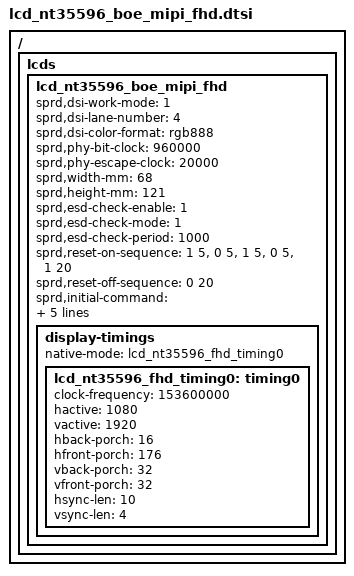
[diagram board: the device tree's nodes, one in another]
// SPDX-License-Identifier: GPL-2.0-only
/*
 * Unisoc NT35696 Truly LCD config DTS file
 *
 * Copyright (C) 2021, Unisoc Inc.
 */
/ {fragment {
	target-path = "/";
	__overlay__ {
		lcds {
			lcd_nt35596_boe_mipi_fhd: lcd_nt35596_boe_mipi_fhd {

				sprd,dsi-work-mode = <1>; /* video burst mode */
				sprd,dsi-lane-number = <4>;
				sprd,dsi-color-format = "rgb888";

				sprd,phy-bit-clock = <960000>; /* kbps */
				sprd,phy-escape-clock = <20000>; /* kHz */

				sprd,width-mm = <68>;
				sprd,height-mm = <121>;

				sprd,esd-check-enable = <1>;
				sprd,esd-check-mode = <1>;
				sprd,esd-check-period = <1000>;
				/* sprd,esd-check-regs = <0x0A>; */
				/* sprd,esd-return-code = <0x9C>; */

				sprd,reset-on-sequence = <1 5>, <0 5>, <1 5>, <0 5>, <1 20>;
				sprd,reset-off-sequence = <0 20>;

				sprd,initial-command = [
					23 00 00 02 FF EE
					23 0A 00 02 18 40 /* OSC ON 10ms */
					23 14 00 02 18 00 /* OSC OFF 20ms */

					23 00 00 02 FF 01
					23 00 00 02 FB 01
					23 00 00 02 00 01
					23 00 00 02 01 55
					23 00 00 02 02 40
					23 00 00 02 05 40
					23 00 00 02 06 94
					23 00 00 02 07 94
					23 00 00 02 08 0C
					23 00 00 02 11 19
					23 00 00 02 12 19
					23 00 00 02 13 03
					23 00 00 02 14 94
					23 00 00 02 15 15
					23 00 00 02 16 15
					23 00 00 02 6D 22
					23 00 00 02 0B AF
					23 00 00 02 0C AF
					23 00 00 02 0E AB
					23 00 00 02 0F A4
					23 00 00 02 58 82
					23 00 00 02 59 02
					23 00 00 02 5A 02
					23 00 00 02 5B 02
					23 00 00 02 5C 82
					23 00 00 02 5D 82
					23 00 00 02 5E 02
					23 00 00 02 5F 02
					23 00 00 02 75 00
					23 00 00 02 76 00
					23 00 00 02 77 00
					23 00 00 02 78 11
					23 00 00 02 79 00
					23 00 00 02 7A 30
					23 00 00 02 7B 00
					23 00 00 02 7C 4A
					23 00 00 02 7D 00
					23 00 00 02 7E 62
					23 00 00 02 7F 00
					23 00 00 02 80 78
					23 00 00 02 81 00
					23 00 00 02 82 8C
					23 00 00 02 83 00
					23 00 00 02 84 9E
					23 00 00 02 85 00
					23 00 00 02 86 AE
					23 00 00 02 87 00
					23 00 00 02 88 E4
					23 00 00 02 89 01
					23 00 00 02 8A 0E
					23 00 00 02 8B 01
					23 00 00 02 8C 4C
					23 00 00 02 8D 01
					23 00 00 02 8E 7B
					23 00 00 02 8F 01
					23 00 00 02 90 C2
					23 00 00 02 91 01
					23 00 00 02 92 FB
					23 00 00 02 93 01
					23 00 00 02 94 FC
					23 00 00 02 95 02
					23 00 00 02 96 34
					23 00 00 02 97 02
					23 00 00 02 98 79
					23 00 00 02 99 02
					23 00 00 02 9A A4
					23 00 00 02 9B 02
					23 00 00 02 9C DD
					23 00 00 02 9D 03
					23 00 00 02 9E 05
					23 00 00 02 9F 03
					23 00 00 02 A0 39
					23 00 00 02 A2 03
					23 00 00 02 A3 48
					23 00 00 02 A4 03
					23 00 00 02 A5 58
					23 00 00 02 A6 03
					23 00 00 02 A7 6A
					23 00 00 02 A9 03
					23 00 00 02 AA 7F
					23 00 00 02 AB 03
					23 00 00 02 AC 98
					23 00 00 02 AD 03
					23 00 00 02 AE B7
					23 00 00 02 AF 03
					23 00 00 02 B0 D7
					23 00 00 02 B1 03
					23 00 00 02 B2 FF
					23 00 00 02 B3 00
					23 00 00 02 B4 00
					23 00 00 02 B5 00
					23 00 00 02 B6 11
					23 00 00 02 B7 00
					23 00 00 02 B8 30
					23 00 00 02 B9 00
					23 00 00 02 BA 4A
					23 00 00 02 BB 00
					23 00 00 02 BC 62
					23 00 00 02 BD 00
					23 00 00 02 BE 78
					23 00 00 02 BF 00
					23 00 00 02 C0 8C
					23 00 00 02 C1 00
					23 00 00 02 C2 9E
					23 00 00 02 C3 00
					23 00 00 02 C4 AE
					23 00 00 02 C5 00
					23 00 00 02 C6 E4
					23 00 00 02 C7 01
					23 00 00 02 C8 0E
					23 00 00 02 C9 01
					23 00 00 02 CA 4C
					23 00 00 02 CB 01
					23 00 00 02 CC 7B
					23 00 00 02 CD 01
					23 00 00 02 CE C2
					23 00 00 02 CF 01
					23 00 00 02 D0 FB
					23 00 00 02 D1 01
					23 00 00 02 D2 FC
					23 00 00 02 D3 02
					23 00 00 02 D4 34
					23 00 00 02 D5 02
					23 00 00 02 D6 79
					23 00 00 02 D7 02
					23 00 00 02 D8 A4
					23 00 00 02 D9 02
					23 00 00 02 DA DD
					23 00 00 02 DB 03
					23 00 00 02 DC 05
					23 00 00 02 DD 03
					23 00 00 02 DE 39
					23 00 00 02 DF 03
					23 00 00 02 E0 48
					23 00 00 02 E1 03
					23 00 00 02 E2 58
					23 00 00 02 E3 03
					23 00 00 02 E4 6A
					23 00 00 02 E5 03
					23 00 00 02 E6 7F
					23 00 00 02 E7 03
					23 00 00 02 E8 98
					23 00 00 02 E9 03
					23 00 00 02 EA B7
					23 00 00 02 EB 03
					23 00 00 02 EC D7
					23 00 00 02 ED 03
					23 00 00 02 EE FF
					23 00 00 02 EF 00
					23 00 00 02 F0 00
					23 00 00 02 F1 00
					23 00 00 02 F2 11
					23 00 00 02 F3 00
					23 00 00 02 F4 30
					23 00 00 02 F5 00
					23 00 00 02 F6 4A
					23 00 00 02 F7 00
					23 00 00 02 F8 62
					23 00 00 02 F9 00
					23 00 00 02 FA 78
					23 00 00 02 FF 02
					23 00 00 02 FB 01
					23 00 00 02 00 00
					23 00 00 02 01 8C
					23 00 00 02 02 00
					23 00 00 02 03 9E
					23 00 00 02 04 00
					23 00 00 02 05 AE
					23 00 00 02 06 00
					23 00 00 02 07 E4
					23 00 00 02 08 01
					23 00 00 02 09 0E
					23 00 00 02 0A 01
					23 00 00 02 0B 4C
					23 00 00 02 0C 01
					23 00 00 02 0D 7B
					23 00 00 02 0E 01
					23 00 00 02 0F C2
					23 00 00 02 10 01
					23 00 00 02 11 FB
					23 00 00 02 12 01
					23 00 00 02 13 FC
					23 00 00 02 14 02
					23 00 00 02 15 34
					23 00 00 02 16 02
					23 00 00 02 17 79
					23 00 00 02 18 02
					23 00 00 02 19 A4
					23 00 00 02 1A 02
					23 00 00 02 1B DD
					23 00 00 02 1C 03
					23 00 00 02 1D 05
					23 00 00 02 1E 03
					23 00 00 02 1F 39
					23 00 00 02 20 03
					23 00 00 02 21 48
					23 00 00 02 22 03
					23 00 00 02 23 58
					23 00 00 02 24 03
					23 00 00 02 25 6A
					23 00 00 02 26 03
					23 00 00 02 27 7F
					23 00 00 02 28 03
					23 00 00 02 29 98
					23 00 00 02 2A 03
					23 00 00 02 2B B7
					23 00 00 02 2D 03
					23 00 00 02 2F D7
					23 00 00 02 30 03
					23 00 00 02 31 FF
					23 00 00 02 32 00
					23 00 00 02 33 00
					23 00 00 02 34 00
					23 00 00 02 35 11
					23 00 00 02 36 00
					23 00 00 02 37 30
					23 00 00 02 38 00
					23 00 00 02 39 4A
					23 00 00 02 3A 00
					23 00 00 02 3B 62
					23 00 00 02 3D 00
					23 00 00 02 3F 78
					23 00 00 02 40 00
					23 00 00 02 41 8C
					23 00 00 02 42 00
					23 00 00 02 43 9E
					23 00 00 02 44 00
					23 00 00 02 45 AE
					23 00 00 02 46 00
					23 00 00 02 47 E4
					23 00 00 02 48 01
					23 00 00 02 49 0E
					23 00 00 02 4A 01
					23 00 00 02 4B 4C
					23 00 00 02 4C 01
					23 00 00 02 4D 7B
					23 00 00 02 4E 01
					23 00 00 02 4F C2
					23 00 00 02 50 01
					23 00 00 02 51 FB
					23 00 00 02 52 01
					23 00 00 02 53 FC
					23 00 00 02 54 02
					23 00 00 02 55 34
					23 00 00 02 56 02
					23 00 00 02 58 79
					23 00 00 02 59 02
					23 00 00 02 5A A4
					23 00 00 02 5B 02
					23 00 00 02 5C DD
					23 00 00 02 5D 03
					23 00 00 02 5E 05
					23 00 00 02 5F 03
					23 00 00 02 60 39
					23 00 00 02 61 03
					23 00 00 02 62 48
					23 00 00 02 63 03
					23 00 00 02 64 58
					23 00 00 02 65 03
					23 00 00 02 66 6A
					23 00 00 02 67 03
					23 00 00 02 68 7F
					23 00 00 02 69 03
					23 00 00 02 6A 98
					23 00 00 02 6B 03
					23 00 00 02 6C B7
					23 00 00 02 6D 03
					23 00 00 02 6E D7
					23 00 00 02 6F 03
					23 00 00 02 70 FF
					23 00 00 02 71 00
					23 00 00 02 72 00
					23 00 00 02 73 00
					23 00 00 02 74 11
					23 00 00 02 75 00
					23 00 00 02 76 30
					23 00 00 02 77 00
					23 00 00 02 78 4A
					23 00 00 02 79 00
					23 00 00 02 7A 62
					23 00 00 02 7B 00
					23 00 00 02 7C 78
					23 00 00 02 7D 00
					23 00 00 02 7E 8C
					23 00 00 02 7F 00
					23 00 00 02 80 9E
					23 00 00 02 81 00
					23 00 00 02 82 AE
					23 00 00 02 83 00
					23 00 00 02 84 E4
					23 00 00 02 85 01
					23 00 00 02 86 0E
					23 00 00 02 87 01
					23 00 00 02 88 4C
					23 00 00 02 89 01
					23 00 00 02 8A 7B
					23 00 00 02 8B 01
					23 00 00 02 8C C2
					23 00 00 02 8D 01
					23 00 00 02 8E FB
					23 00 00 02 8F 01
					23 00 00 02 90 FC
					23 00 00 02 91 02
					23 00 00 02 92 34
					23 00 00 02 93 02
					23 00 00 02 94 79
					23 00 00 02 95 02
					23 00 00 02 96 A4
					23 00 00 02 97 02
					23 00 00 02 98 DD
					23 00 00 02 99 03
					23 00 00 02 9A 05
					23 00 00 02 9B 03
					23 00 00 02 9C 39
					23 00 00 02 9D 03
					23 00 00 02 9E 48
					23 00 00 02 9F 03
					23 00 00 02 A0 58
					23 00 00 02 A2 03
					23 00 00 02 A3 6A
					23 00 00 02 A4 03
					23 00 00 02 A5 7F
					23 00 00 02 A6 03
					23 00 00 02 A7 98
					23 00 00 02 A9 03
					23 00 00 02 AA B7
					23 00 00 02 AB 03
					23 00 00 02 AC D7
					23 00 00 02 AD 03
					23 00 00 02 AE FF
					23 00 00 02 AF 00
					23 00 00 02 B0 00
					23 00 00 02 B1 00
					23 00 00 02 B2 11
					23 00 00 02 B3 00
					23 00 00 02 B4 30
					23 00 00 02 B5 00
					23 00 00 02 B6 4A
					23 00 00 02 B7 00
					23 00 00 02 B8 62
					23 00 00 02 B9 00
					23 00 00 02 BA 78
					23 00 00 02 BB 00
					23 00 00 02 BC 8C
					23 00 00 02 BD 00
					23 00 00 02 BE 9E
					23 00 00 02 BF 00
					23 00 00 02 C0 AE
					23 00 00 02 C1 00
					23 00 00 02 C2 E4
					23 00 00 02 C3 01
					23 00 00 02 C4 0E
					23 00 00 02 C5 01
					23 00 00 02 C6 4C
					23 00 00 02 C7 01
					23 00 00 02 C8 7B
					23 00 00 02 C9 01
					23 00 00 02 CA C2
					23 00 00 02 CB 01
					23 00 00 02 CC FB
					23 00 00 02 CD 01
					23 00 00 02 CE FC
					23 00 00 02 CF 02
					23 00 00 02 D0 34
					23 00 00 02 D1 02
					23 00 00 02 D2 79
					23 00 00 02 D3 02
					23 00 00 02 D4 A4
					23 00 00 02 D5 02
					23 00 00 02 D6 DD
					23 00 00 02 D7 03
					23 00 00 02 D8 05
					23 00 00 02 D9 03
					23 00 00 02 DA 39
					23 00 00 02 DB 03
					23 00 00 02 DC 48
					23 00 00 02 DD 03
					23 00 00 02 DE 58
					23 00 00 02 DF 03
					23 00 00 02 E0 6A
					23 00 00 02 E1 03
					23 00 00 02 E2 7F
					23 00 00 02 E3 03
					23 00 00 02 E4 98
					23 00 00 02 E5 03
					23 00 00 02 E6 B7
					23 00 00 02 E7 03
					23 00 00 02 E8 D7
					23 00 00 02 E9 03
					23 00 00 02 EA FF
					23 00 00 02 FF 05
					23 00 00 02 FB 01
					23 00 00 02 00 00
					23 00 00 02 01 01
					23 00 00 02 02 0B
					23 00 00 02 03 0C
					23 00 00 02 04 00
					23 00 00 02 05 03
					23 00 00 02 06 00
					23 00 00 02 07 04
					23 00 00 02 08 00
					23 00 00 02 09 00
					23 00 00 02 0A 00
					23 00 00 02 0B 00
					23 00 00 02 0C 00
					23 00 00 02 0D 17
					23 00 00 02 0E 15
					23 00 00 02 0F 13
					23 00 00 02 10 00
					23 00 00 02 11 01
					23 00 00 02 12 0B
					23 00 00 02 13 0C
					23 00 00 02 14 00
					23 00 00 02 15 03
					23 00 00 02 16 00
					23 00 00 02 17 04
					23 00 00 02 18 00
					23 00 00 02 19 00
					23 00 00 02 1A 00
					23 00 00 02 1B 00
					23 00 00 02 1C 00
					23 00 00 02 1D 17
					23 00 00 02 1E 15
					23 00 00 02 1F 13
					23 00 00 02 20 09
					23 00 00 02 21 02
					23 00 00 02 22 00
					23 00 00 02 23 00
					23 00 00 02 24 00
					23 00 00 02 25 3D
					23 00 00 02 29 38
					23 00 00 02 2A 2B
					23 00 00 02 2F 02
					23 00 00 02 30 01
					23 00 00 02 31 49
					23 00 00 02 32 23
					23 00 00 02 33 01
					23 00 00 02 34 05
					23 00 00 02 35 74
					23 00 00 02 36 00
					23 00 00 02 37 2D
					23 00 00 02 38 08
					23 00 00 02 92 94
					23 00 00 02 5B 00
					23 00 00 02 5F 1D
					23 00 00 02 63 00
					23 00 00 02 67 04
					23 00 00 02 6C 55
					23 00 00 02 7A 00
					23 00 00 02 7B A2
					23 00 00 02 7C D8
					23 00 00 02 7D 50
					23 00 00 02 7E 0A
					23 00 00 02 7F 1C
					23 00 00 02 81 06
					23 00 00 02 82 02
					23 00 00 02 84 03
					23 00 00 02 85 05
					23 00 00 02 C5 20
					23 00 00 02 80 00
					23 00 00 02 83 00
					23 00 00 02 93 08
					23 00 00 02 94 0A
					23 00 00 02 8A 33
					23 00 00 02 A4 0F
					23 00 00 02 9B 0F
					23 00 00 02 9D B0
					23 00 00 02 E7 83
					23 00 00 02 E3 02
					23 00 00 02 FF 00
					23 00 00 02 D2 03
					23 00 00 02 D3 24
					23 00 00 02 D4 20
					23 00 00 02 35 00
					23 00 00 02 BA 03
					13 78 00 01 11
					13 64 00 01 29
					];
				sprd,sleep-in-command =  [
					13 0A 00 01 28
					13 78 00 01 10
					23 0a 00 02 4F 01
					];
				sprd,sleep-out-command = [
					13 78 00 01 11
					13 64 00 01 29
					];

				display-timings {
					native-mode = <&lcd_nt35596_fhd_timing0>;

					lcd_nt35596_fhd_timing0: timing0 {
						clock-frequency = <153600000>;
						hactive = <1080>;
						vactive = <1920>;
						hback-porch = <16>;
						hfront-porch = <176>;
						vback-porch = <32>;
						vfront-porch = <32>;
						hsync-len = <10>;
						vsync-len = <4>;
					};
				};
			};
		};
	};
};};
